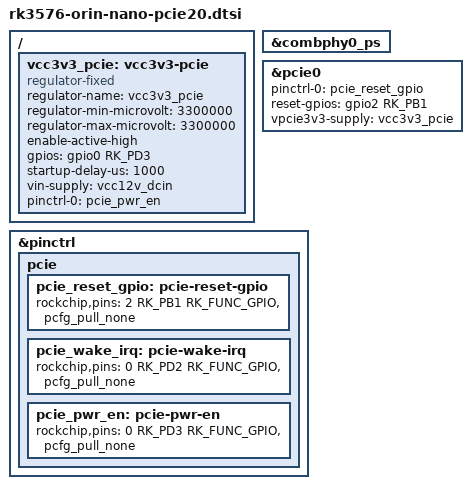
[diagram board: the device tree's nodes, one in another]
// SPDX-License-Identifier: (GPL-2.0+ OR MIT)
/*
 * Guangzhou Easy EAI Technology Co., Ltd.
 *
 */

/ {
	vcc3v3_pcie: vcc3v3-pcie {
		compatible = "regulator-fixed";
		regulator-name = "vcc3v3_pcie";
		regulator-min-microvolt = <3300000>;
		regulator-max-microvolt = <3300000>;
		enable-active-high;
		gpios = <&gpio0 RK_PD3 GPIO_ACTIVE_HIGH>;
		startup-delay-us = <1000>;
		vin-supply = <&vcc12v_dcin>;
		pinctrl-names = "default";
		pinctrl-0 = <&pcie_pwr_en>;
	};
};

/*PHY*/
&combphy0_ps {
	status = "okay";
};

/* 控制器 */
&pcie0 {
	pinctrl-names = "default";
	pinctrl-0 = <&pcie_reset_gpio>;
	reset-gpios = <&gpio2 RK_PB1 GPIO_ACTIVE_HIGH>;
	vpcie3v3-supply = <&vcc3v3_pcie>;
	status = "okay";
};

&pinctrl {
	pcie {
		pcie_reset_gpio: pcie-reset-gpio {
			rockchip,pins = <2 RK_PB1 RK_FUNC_GPIO &pcfg_pull_none>;
		};
		pcie_wake_irq: pcie-wake-irq {
			rockchip,pins = <0 RK_PD2 RK_FUNC_GPIO &pcfg_pull_none>;
		};
		pcie_pwr_en: pcie-pwr-en {
			rockchip,pins = <0 RK_PD3 RK_FUNC_GPIO &pcfg_pull_none>;
		};
	};
};

